# GD32H71x_72x register map
File version: 1.0
CPU: CM7 r1p2, little endian, MPU, FPU, 4 interrupt priority bits
Registers are 32-bit, read-write, reset 0x0 unless marked. A register's access mark holds for its fields unless they carry their own. Offsets are from the block's base; [hi:lo] are bit positions; {n}, {i} and the like mark numbered series.

## DTM_CAN0 — DTM controller area network
Base 0x4001B000
Same registers: DTM_CAN1 0x4001B800, DTM_CAN2 0x4001C000
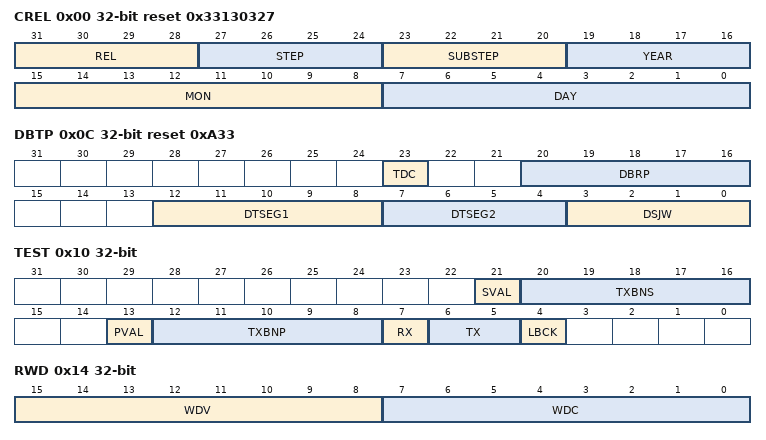
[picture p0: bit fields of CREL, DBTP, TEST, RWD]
0x00 CREL ro reset 0x33130327 — Core release register
  [31:28] REL — Core release (One digit, BCD-coded)
  [27:24] STEP — Step of core release (One digit, BCD-coded)
  [23:20] SUBSTEP — Sub-step of core release (One digit, BCD-coded)
  [19:16] YEAR — Time stamp year (One digit, BCD-coded)
  [15:8] MON — Time stamp month (Two digit, BCD-coded)
  [7:0] DAY — Time stamp day (Two digit, BCD-coded)
0x04 ENDN ro reset 0x87654321 — Endian register
  [31:0] ETV — Endianness test value
0x0C DBTP reset 0xA33 — Data bit timing and prescaler register
  [23] TDC — Transceiver delay compensation
  [20:16] DBRP — Data bit rate prescaler
  [12:8] DTSEG1 — Data time segment before sample point
  [7:4] DTSEG2 — Data time segment after sample point
  [3:0] DSJW — Data (re) synchronization jump width
0x10 TEST access per field
  [21] SVAL ro — Started Valid
  [20:16] TXBNS ro — Tx Buffer number started
  [13] PVAL ro — Prepared Valid
  [12:8] TXBNP ro — Tx Buffer number prepared
  [7] RX ro — Receive pin
  [6:5] TX rw — Control of transmit pin
  [4] LBCK rw — Loop back mode
0x14 RWD access per field — RAM watchdog register
  [15:8] WDV ro — Watchdog value
  [7:0] WDC rw — Watchdog configuration
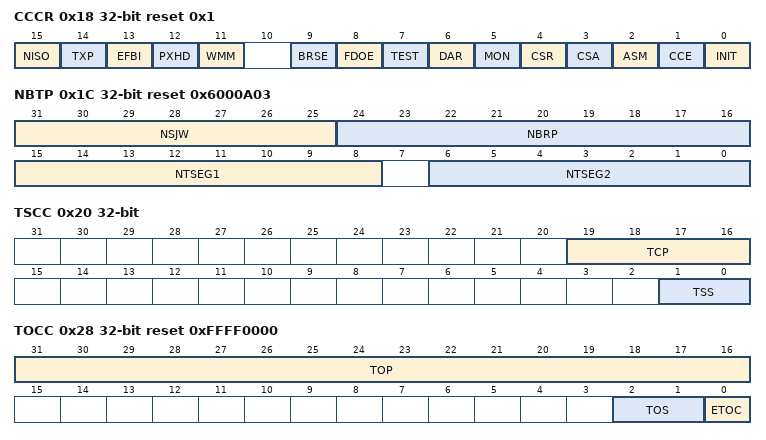
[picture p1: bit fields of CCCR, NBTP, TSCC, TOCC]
0x18 CCCR access per field reset 0x1 — CC control register
  [15] NISO rw — Non ISO operation
  [14] TXP rw — Transmit pause
  [13] EFBI rw — Edge filtering during bus integration
  [12] PXHD rw — Protocol exception handling disable
  [11] WMM rw — Wide message marker
  [9] BRSE rw — Bit rate switch enable
  [8] FDOE rw — FD operation enable
  [7] TEST rw — Test mode enable
  [6] DAR rw — Disable automatic retransmission
  [5] MON rw — Bus monitoring mode
  [4] CSR rw — Clock stop request
  [3] CSA ro — Clock stop acknowledge
  [2] ASM rw — Restricted operation mode
  [1] CCE rw — Configuration change enable
  [0] INIT rw — Initialization
0x1C NBTP reset 0x6000A03 — Nominal bit timing and prescaler register
  [31:25] NSJW — Nominal (Re) synchronization jump width
  [24:16] NBRP — Nominal baud rate prescaler
  [15:8] NTSEG1 — Nominal Time segment before sample point
  [6:0] NTSEG2 — Nominal time segment after sample point
0x20 TSCC — Timestamp counter configuration register
  [19:16] TCP — Timestamp counter prescaler
  [1:0] TSS — Timestamp select
0x24 TSCV — Timestamp counter value register
  [15:0] TSC — Timestamp Counter
0x28 TOCC reset 0xFFFF0000 — Timeout counter configuration register
  [31:16] TOP — Timeout period
  [2:1] TOS — Timeout select
  [0] ETOC — Enable timeout counter
0x2C TOCV reset 0xFFFF — Timeout counter value register
  [15:0] TOC — Timeout counter
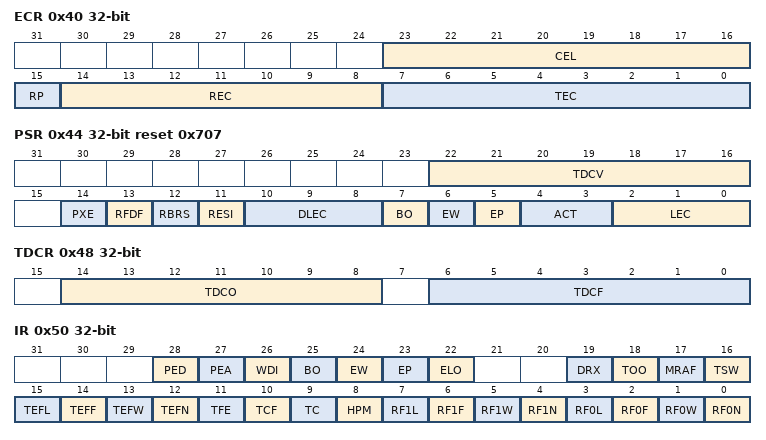
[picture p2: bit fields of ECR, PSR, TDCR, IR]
0x40 ECR access per field — Error counter register
  [23:16] CEL rw — CAN error logging
  [15] RP ro — Receive error passive
  [14:8] REC ro — Receive error counter
  [7:0] TEC ro — Transmit error counter
0x44 PSR ro reset 0x707 — Protocol status register
  [22:16] TDCV — Transmitter delay compensation value
  [14] PXE — Protocol exception event
  [13] RFDF — Received a CAN FD message
  [12] RBRS — BRS flag of last received CAN FD message
  [11] RESI — ESI flag of last received CAN FD message
  [10:8] DLEC — Data phase last error code
  [7] BO — Bus_Off status
  [6] EW — Warning status
  [5] EP — Error passive
  [4:3] ACT — Activity
  [2:0] LEC — Last error code
0x48 TDCR — Transmitter delay compensation register
  [14:8] TDCO — Transmitter delay compensation SSP offset
  [6:0] TDCF — Transmitter delay compensation filter window length
0x50 IR — Interrupt register
  [28] PED — Protocol error in data phase (data bit time is used)
  [27] PEA — Protocol error in arbitration phase (nominal bit time is used)
  [26] WDI — Watchdog interrupt
  [25] BO — Bus_Off status
  [24] EW — Warning status
  [23] EP — Error passive
  [22] ELO — Error logging overflow
  [19] DRX — Message stored to dedicated Rx Buffer
  [18] TOO — Timeout occurred
  [17] MRAF — Message RAM access failure
  [16] TSW — Timestamp wraparound
  [15] TEFL — Tx Event FIFO event lost
  [14] TEFF — Tx Event FIFO full
  [13] TEFW — Tx Event FIFO watermark reached
  [12] TEFN — Tx Event FIFO new entry
  [11] TFE — Tx FIFO empty
  [10] TCF — Transmission cancellation finished
  [9] TC — Transmission completed
  [8] HPM — High priority message
  [7] RF1L — Rx FIFO 1 message lost
  [6] RF1F — Rx FIFO 1 full
  [5] RF1W — Rx FIFO 1 watermark reached
  [4] RF1N — Rx FIFO 1 new message
  [3] RF0L — Rx FIFO 0 message lost
  [2] RF0F — Rx FIFO 0 full
  [1] RF0W — Rx FIFO 0 watermark reached
  [0] RF0N — Rx FIFO 0 new message
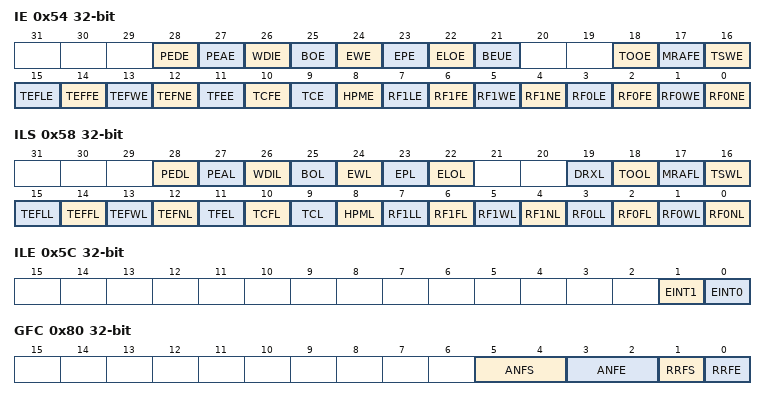
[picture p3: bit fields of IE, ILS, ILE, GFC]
0x54 IE — Interrupt enable register
  [28] PEDE — Protocol error in data phase enable
  [27] PEAE — Protocol error in arbitration phase enable
  [26] WDIE — Watchdog interrupt enable
  [25] BOE — Bus_Off status interrupt enable
  [24] EWE — Warning status interrupt enable
  [23] EPE — Error passive interrupt enable
  [22] ELOE — Error logging overflow interrupt enable
  [21] BEUE — Must be kept at reset value
  [18] TOOE — Timeout occurred interrupt enable
  [17] MRAFE — Message RAM access failure interrupt enable
  [16] TSWE — Timestamp wraparound interrupt enable
  [15] TEFLE — Tx Event FIFO event lost interrupt enable
  [14] TEFFE — Tx Event FIFO full interrupt enable
  [13] TEFWE — Tx Event FIFO watermark reached interrupt enable
  [12] TEFNE — Tx Event FIFO new entry interrupt enable
  [11] TFEE — Tx FIFO empty interrupt enable
  [10] TCFE — Transmission cancellation finished interrupt enable
  [9] TCE — Transmission completed interrupt enable
  [8] HPME — High priority message interrupt enable
  [7] RF1LE — Rx FIFO 1 message lost interrupt enable
  [6] RF1FE — Rx FIFO 1 full interrupt enable
  [5] RF1WE — Rx FIFO 1 watermark reached interrupt enable
  [4] RF1NE — Rx FIFO 1 new message interrupt enable
  [3] RF0LE — Rx FIFO 0 message lost interrupt enable
  [2] RF0FE — Rx FIFO 0 full interrupt enable
  [1] RF0WE — Rx FIFO 0 Watermark Reached Interrupt Enable
  [0] RF0NE — Rx FIFO 0 New Message Interrupt Enable
0x58 ILS — Interrupt line select register
  [28] PEDL — Protocol error in data phase line
  [27] PEAL — Protocol error in arbitration phase line
  [26] WDIL — Watchdog interrupt line
  [25] BOL — Bus_Off status interrupt line
  [24] EWL — Warning status interrupt line
  [23] EPL — Error passive interrupt line
  [22] ELOL — Error logging overflow interrupt line
  [19] DRXL — Message stored to dedicated Rx Buffer interrupt line
  [18] TOOL — Timeout occurred interrupt line
  [17] MRAFL — Message RAM access failure interrupt line
  [16] TSWL — Timestamp wraparound interrupt line
  [15] TEFLL — Tx Event FIFO event lost interrupt line
  [14] TEFFL — Tx Event FIFO full interrupt line
  [13] TEFWL — Tx Event FIFO watermark reached interrupt line
  [12] TEFNL — Tx Event FIFO new entry interrupt line
  [11] TFEL — Tx FIFO empty interrupt line
  [10] TCFL — Transmission cancellation finished interrupt line
  [9] TCL — Transmission completed interrupt line
  [8] HPML — High priority message interrupt line
  [7] RF1LL — Rx FIFO 1 message lost interrupt line
  [6] RF1FL — Rx FIFO 1 full interrupt line
  [5] RF1WL — Rx FIFO 1 watermark reached interrupt line
  [4] RF1NL — Rx FIFO 1 new message interrupt line
  [3] RF0LL — Rx FIFO 0 message lost interrupt line
  [2] RF0FL — Rx FIFO 0 full interrupt line
  [1] RF0WL — Rx FIFO 0 watermark reached interrupt line
  [0] RF0NL — Rx FIFO 0 new message interrupt line
0x5C ILE — Interrupt line enable register
  [1] EINT1 — Enable Interrupt Line 1
  [0] EINT0 — Enable Interrupt Line 0
0x80 GFC — Global filter configuration register
  [5:4] ANFS — Accept non-matching frames standard
  [3:2] ANFE — Accept non-matching frames extended
  [1] RRFS — Reject remote frames standard
  [0] RRFE — Reject remote frames extended
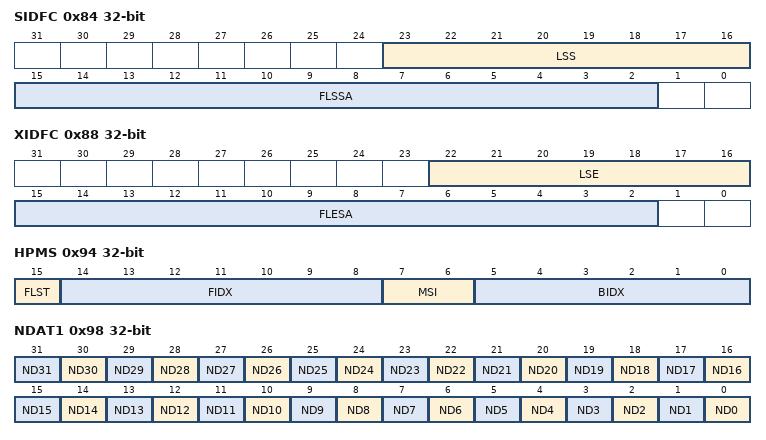
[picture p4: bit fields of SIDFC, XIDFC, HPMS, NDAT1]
0x84 SIDFC — Standard ID filter configuration register
  [23:16] LSS — List size standard
  [15:2] FLSSA — Filter list standard start address
0x88 XIDFC — Extended ID filter configuration register
  [22:16] LSE — List size extended
  [15:2] FLESA — Filter list extended start address
0x90 XIDAM reset 0x1FFFFFFF — Extended ID and mask register
  [28:0] EIDM — Extended ID Mask
0x94 HPMS ro — High priority message status register
  [15] FLST — Filter list
  [14:8] FIDX — Filter index
  [7:6] MSI — Message storage indicator
  [5:0] BIDX — Buffer index
0x98 NDAT1 — New data 1 register
  [n] ND{n} (n=0..31) — New data {n}
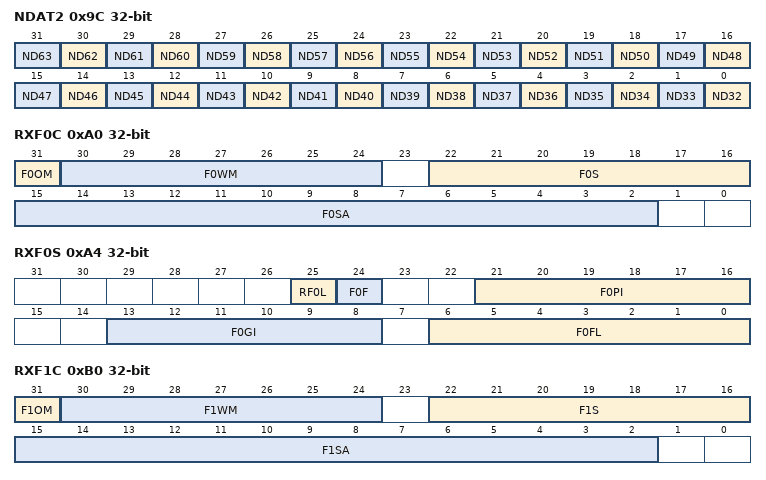
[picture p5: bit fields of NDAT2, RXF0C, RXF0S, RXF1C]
0x9C NDAT2 — New data 2 register
  [n-32] ND{n} (n=32..63) — New data {n-32}
0xA0 RXF0C — Rx FIFO 0 Configuration register
  [31] F0OM — FIFO 0 operation mode
  [30:24] F0WM — Rx FIFO 0 watermark
  [22:16] F0S — Rx FIFO 0 size
  [15:2] F0SA — Rx FIFO 0 start address
0xA4 RXF0S ro — Rx FIFO 0 status register
  [25] RF0L — Rx FIFO 0 message lost
  [24] F0F — Rx FIFO 0 full
  [21:16] F0PI — Rx FIFO 0 put index
  [13:8] F0GI — Rx FIFO 0 get index
  [6:0] F0FL — Rx FIFO 0 fill level
0xA8 RXF0A — Rx FIFO 0 acknowledge register
  [5:0] F0AI — Rx FIFO 0 acknowledge index
0xAC RXBC — Rx buffer configuration register
  [15:2] RBSA — Rx Buffer start address
0xB0 RXF1C — Rx FIFO 1 configuration register
  [31] F1OM — FIFO 1 operation mode
  [30:24] F1WM — Rx FIFO 1 watermark
  [22:16] F1S — Rx FIFO 1 size
  [15:2] F1SA — Rx FIFO 1 start address
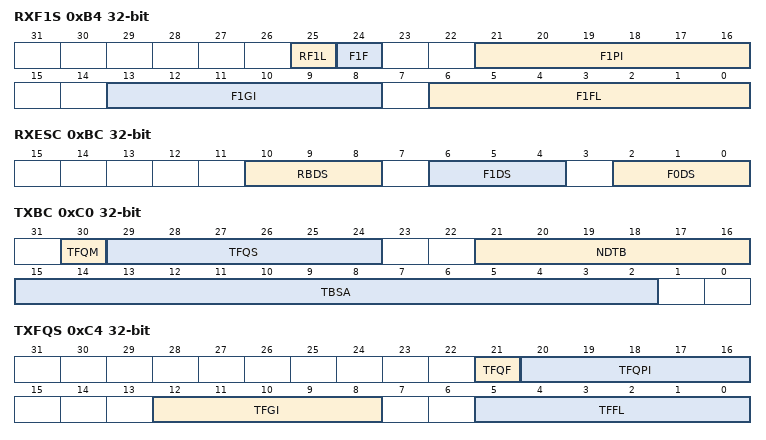
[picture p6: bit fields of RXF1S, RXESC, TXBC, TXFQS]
0xB4 RXF1S ro — Rx FIFO 1 status register
  [25] RF1L — Rx FIFO 1 message lost
  [24] F1F — Rx FIFO 1 full
  [21:16] F1PI — Rx FIFO 1 put index
  [13:8] F1GI — Rx FIFO 1 get index
  [6:0] F1FL — Rx FIFO 1 fill level
0xB8 RXF1A — Rx FIFO 1 acknowledge register
  [5:0] F1AI — Rx FIFO 1 acknowledge index
0xBC RXESC — Rx buffer / FIFO element size configuration register
  [10:8] RBDS — Rx buffer data field size
  [6:4] F1DS — Rx FIFO 1 data field size
  [2:0] F0DS — Rx FIFO 0 data field size
0xC0 TXBC — Tx buffer configuration register
  [30] TFQM — Tx FIFO / Queue mode
  [29:24] TFQS — Tx FIFO / Queue size
  [21:16] NDTB — Number of dedicated transmit buffers
  [15:2] TBSA — Tx Buffers start address
0xC4 TXFQS ro — Tx FIFO / Queue status register
  [21] TFQF — Tx FIFO / Queue full
  [20:16] TFQPI — Tx FIFO/Queue put index
  [12:8] TFGI — Tx FIFO get index
  [5:0] TFFL — Tx FIFO free level
0xC8 TXESC — Tx Buffer Element Size Configuration register
  [2:0] TBDS — Tx Buffer data field size
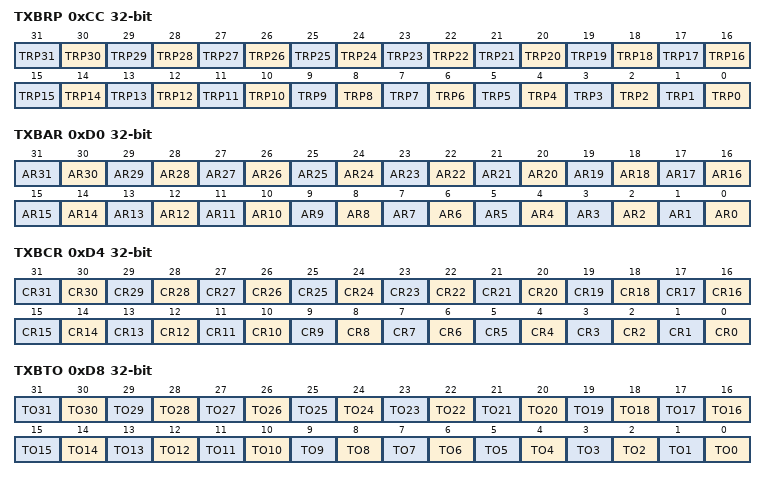
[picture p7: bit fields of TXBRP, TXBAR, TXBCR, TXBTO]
0xCC TXBRP ro — Tx buffer request pending register
  [n] TRP{n} (n=0..31) — Transmission request pending {n}
0xD0 TXBAR — Tx buffer add request register
  [n] AR{n} (n=0..31) — Add request {n}
0xD4 TXBCR — Tx buffer cancellation request register
  [n] CR{n} (n=0..31) — Cancellation request {n}
0xD8 TXBTO ro — Tx buffer transmission occurred register
  [n] TO{n} (n=0..31) — Transmission occurred {n}
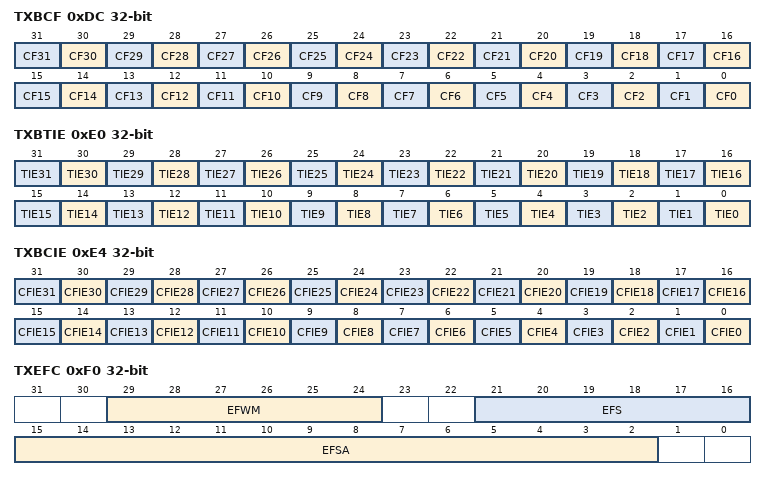
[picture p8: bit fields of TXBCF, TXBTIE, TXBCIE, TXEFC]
0xDC TXBCF ro — Tx buffer cancellation finished register
  [n] CF{n} (n=0..31) — Cancellation finished {n}
0xE0 TXBTIE — Tx buffer transmission interrupt enable register
  [n] TIE{n} (n=0..31) — Transmission interrupt {n} enable
0xE4 TXBCIE — Tx buffer cancellation finished interrupt enable register
  [n] CFIE{n} (n=0..31) — Cancellation finished interrupt {n} enable
0xF0 TXEFC — Tx event FIFO configuration register
  [29:24] EFWM — Event FIFO watermark
  [21:16] EFS — Event FIFO size
  [15:2] EFSA — Event FIFO start address
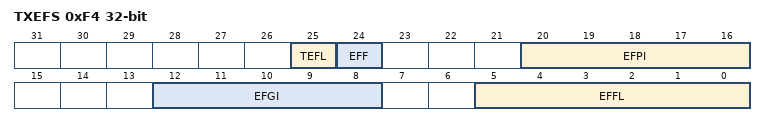
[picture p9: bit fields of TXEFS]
0xF4 TXEFS ro — Tx event FIFO status register
  [25] TEFL — Tx Event FIFO element lost
  [24] EFF — Event FIFO full
  [20:16] EFPI — Event FIFO put index
  [12:8] EFGI — Event FIFO get index
  [5:0] EFFL — Event FIFO fill level
0xF8 TXEFA — Tx event FIFO acknowledge register
  [4:0] EFAI — Event FIFO acknowledge index
